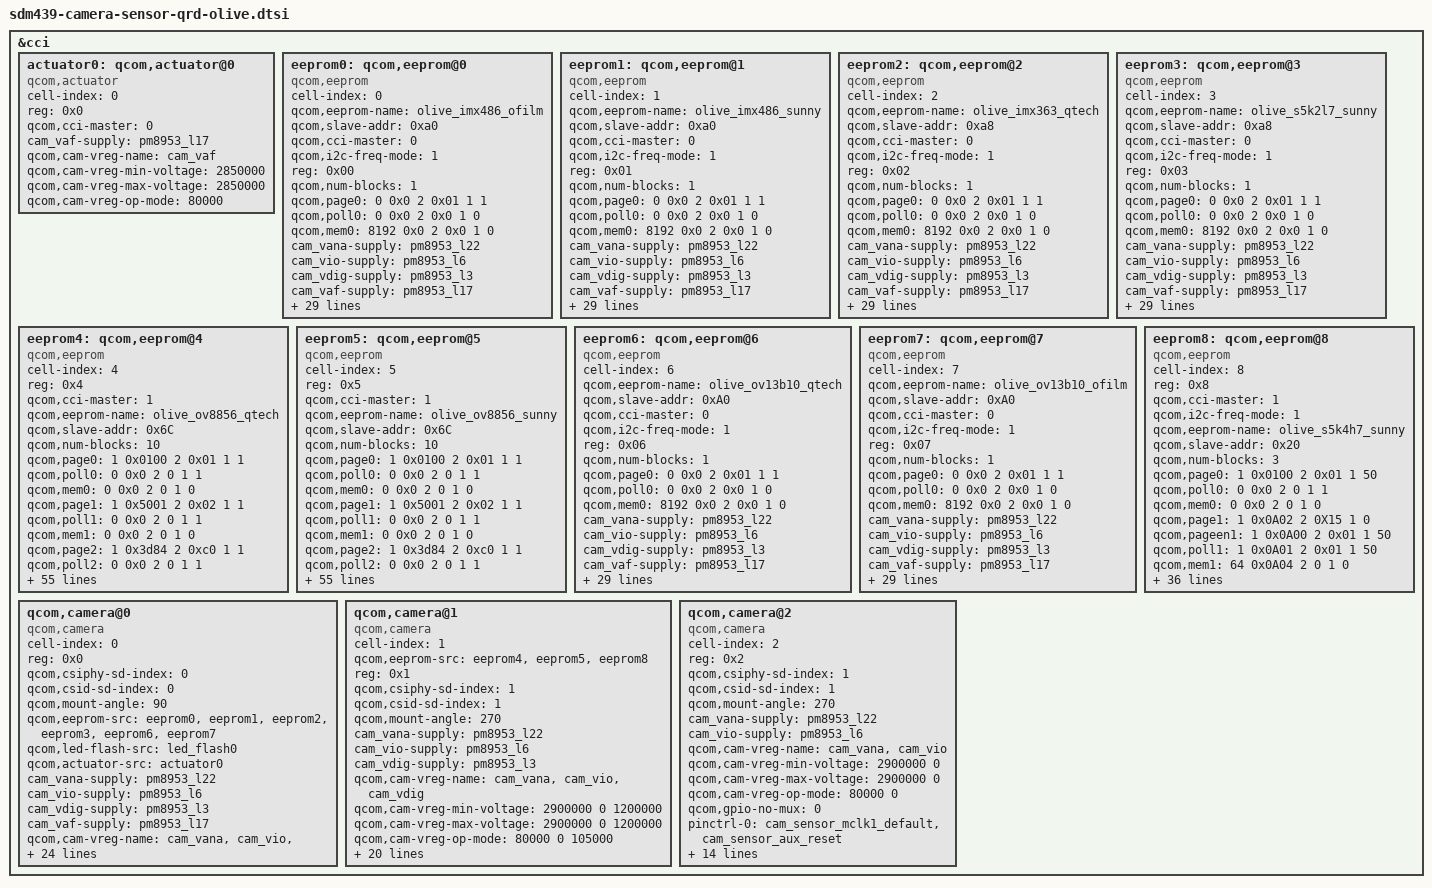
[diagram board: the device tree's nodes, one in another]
/*
 * Copyright (c) 2015-2016, 2018 The Linux Foundation. All rights reserved.
 * Copyright (C) 2021 XiaoMi, Inc.
 *
 * This program is free software; you can redistribute it and/or modify
 * it under the terms of the GNU General Public License version 2 and
 * only version 2 as published by the Free Software Foundation.
 *
 * This program is distributed in the hope that it will be useful,
 * but WITHOUT ANY WARRANTY; without even the implied warranty of
 * MERCHANTABILITY or FITNESS FOR A PARTICULAR PURPOSE.  See the
 * GNU General Public License for more details.
 */

#include <dt-bindings/clock/msm-clocks-8952.h>


&cci {
	actuator0: qcom,actuator@0 {
		cell-index = <0>;
		reg = <0x0>;
		compatible = "qcom,actuator";
		qcom,cci-master = <0>;
		cam_vaf-supply = <&pm8953_l17>;
		qcom,cam-vreg-name = "cam_vaf";
		qcom,cam-vreg-min-voltage = <2850000>;
		qcom,cam-vreg-max-voltage = <2850000>;
		qcom,cam-vreg-op-mode = <80000>;
	};

	eeprom0: qcom,eeprom@0 {
		cell-index = <0>;
		qcom,eeprom-name = "olive_imx486_ofilm";
		compatible = "qcom,eeprom";
		qcom,slave-addr = <0xa0>;
		qcom,cci-master = <0>;
		qcom,i2c-freq-mode = <1>;
		reg = <0x00>;
		qcom,num-blocks = <1>;
		qcom,page0 = <0 0x0 2 0x01 1 1>;
		qcom,poll0 = <0 0x0 2 0x0 1 0>;
		qcom,mem0 = <8192 0x0 2 0x0 1 0>;
		cam_vana-supply = <&pm8953_l22>;
		cam_vio-supply = <&pm8953_l6>;
		cam_vdig-supply = <&pm8953_l3>;
		cam_vaf-supply = <&pm8953_l17>;
		qcom,cam-vreg-name = "cam_vana", "cam_vio","cam_vdig", "cam_vaf";
		qcom,cam-vreg-min-voltage = <2900000 0 1200000 2850000>;
		qcom,cam-vreg-max-voltage = <2900000 0 1200000 2850000>;
		qcom,cam-vreg-op-mode = <80000 0 200000 100000>;
		pinctrl-names = "cam_default", "cam_suspend";
		pinctrl-0 = <&cam_sensor_mclk0_default
				&cam_sensor_rear_reset
				&cam_sensor_rear_vana>;
		pinctrl-1 = <&cam_sensor_mclk0_sleep
				&cam_sensor_rear_reset_sleep
				&cam_sensor_rear_vana_sleep>;
		gpios = <&tlmm 26 0>,
			<&tlmm 36 0>,
			<&tlmm 35 0>;
		qcom,gpio-reset = <1>;
		qcom,gpio-vana = <2>;
		qcom,gpio-req-tbl-num = <0 1 2>;
		qcom,gpio-req-tbl-flags = <1 0 0>;
		qcom,gpio-req-tbl-label = "CAMIF_MCLK0",
			"CAM_RESET0",
			"CAM_VANA";
		status = "ok";
		clocks = <&clock_gcc clk_mclk0_clk_src>,
			<&clock_gcc clk_gcc_camss_mclk0_clk>;
		clock-names = "cam_src_clk", "cam_clk";
		qcom,clock-rates = <24000000 0>;
		qcom,cam-power-seq-type = "sensor_vreg", "sensor_vreg",
				"sensor_vreg", "sensor_clk",
				"sensor_gpio";
		qcom,cam-power-seq-val = "cam_vdig", "cam_vana", "cam_vio",
			"sensor_cam_mclk","sensor_gpio_reset";
		qcom,cam-power-seq-cfg-val = <0 0 0 24000000 1>;
		qcom,cam-power-seq-delay = <0 0 0 1 5>;
	};

	eeprom1: qcom,eeprom@1 {
		cell-index = <1>;
		qcom,eeprom-name = "olive_imx486_sunny";
		compatible = "qcom,eeprom";
		qcom,slave-addr = <0xa0>;
		qcom,cci-master = <0>;
		qcom,i2c-freq-mode = <1>;
		reg = <0x01>;
		qcom,num-blocks = <1>;
		qcom,page0 = <0 0x0 2 0x01 1 1>;
		qcom,poll0 = <0 0x0 2 0x0 1 0>;
		qcom,mem0 = <8192 0x0 2 0x0 1 0>;
		cam_vana-supply = <&pm8953_l22>;
		cam_vio-supply = <&pm8953_l6>;
		cam_vdig-supply = <&pm8953_l3>;
		cam_vaf-supply = <&pm8953_l17>;
		qcom,cam-vreg-name = "cam_vana", "cam_vio",
			"cam_vdig", "cam_vaf";
		qcom,cam-vreg-min-voltage = <2900000 0 1200000 2850000>;
		qcom,cam-vreg-max-voltage = <2900000 0 1200000 2850000>;
		qcom,cam-vreg-op-mode = <80000 0 200000 100000>;
		pinctrl-names = "cam_default", "cam_suspend";
		pinctrl-0 = <&cam_sensor_mclk0_default
				&cam_sensor_rear_reset
				&cam_sensor_rear_vana>;
		pinctrl-1 = <&cam_sensor_mclk0_sleep
				&cam_sensor_rear_reset_sleep
				&cam_sensor_rear_vana_sleep>;
		gpios = <&tlmm 26 0>,
			<&tlmm 36 0>,
			<&tlmm 35 0>;
		qcom,gpio-reset = <1>;
		qcom,gpio-vana = <2>;
		qcom,gpio-req-tbl-num = <0 1 2>;
		qcom,gpio-req-tbl-flags = <1 0 0>;
		qcom,gpio-req-tbl-label = "CAMIF_MCLK0",
			"CAM_RESET0",
			"CAM_VANA";
		status = "ok";
		clocks = <&clock_gcc clk_mclk0_clk_src>,
			<&clock_gcc clk_gcc_camss_mclk0_clk>;
		clock-names = "cam_src_clk", "cam_clk";
		qcom,clock-rates = <24000000 0>;
		qcom,cam-power-seq-type = "sensor_vreg", "sensor_vreg",
				"sensor_vreg", "sensor_clk",
				"sensor_gpio";
		qcom,cam-power-seq-val = "cam_vdig", "cam_vana", "cam_vio",
			"sensor_cam_mclk","sensor_gpio_reset";
		qcom,cam-power-seq-cfg-val = <0 0 0 24000000 1>;
		qcom,cam-power-seq-delay = <0 0 0 1 5>;
	};

	eeprom2: qcom,eeprom@2 {
		cell-index = <2>;
		qcom,eeprom-name = "olive_imx363_qtech";
		compatible = "qcom,eeprom";
		qcom,slave-addr = <0xa8>;
		qcom,cci-master = <0>;
		qcom,i2c-freq-mode = <1>;
		reg = <0x02>;
		qcom,num-blocks = <1>;
		qcom,page0 = <0 0x0 2 0x01 1 1>;
		qcom,poll0 = <0 0x0 2 0x0 1 0>;
		qcom,mem0 = <8192 0x0 2 0x0 1 0>;
		cam_vana-supply = <&pm8953_l22>;
		cam_vio-supply = <&pm8953_l6>;
		cam_vdig-supply = <&pm8953_l3>;
		cam_vaf-supply = <&pm8953_l17>;
		qcom,cam-vreg-name = "cam_vana", "cam_vio",
			"cam_vdig", "cam_vaf";
		qcom,cam-vreg-min-voltage = <2900000 0 1200000 2850000>;
		qcom,cam-vreg-max-voltage = <2900000 0 1200000 2850000>;
		qcom,cam-vreg-op-mode = <80000 0 200000 100000>;
		pinctrl-names = "cam_default", "cam_suspend";
		pinctrl-0 = <&cam_sensor_mclk0_default
				&cam_sensor_rear_reset
				&cam_sensor_rear_vana>;
		pinctrl-1 = <&cam_sensor_mclk0_sleep
				&cam_sensor_rear_reset_sleep
				&cam_sensor_rear_vana_sleep>;
		gpios = <&tlmm 26 0>,
			<&tlmm 36 0>,
			<&tlmm 35 0>;
		qcom,gpio-reset = <1>;
		qcom,gpio-vana = <2>;
		qcom,gpio-req-tbl-num = <0 1 2>;
		qcom,gpio-req-tbl-flags = <1 0 0>;
		qcom,gpio-req-tbl-label = "CAMIF_MCLK0",
			"CAM_RESET0",
			"CAM_VANA";
		status = "ok";
		clocks = <&clock_gcc clk_mclk0_clk_src>,
			<&clock_gcc clk_gcc_camss_mclk0_clk>;
		clock-names = "cam_src_clk", "cam_clk";
		qcom,clock-rates = <24000000 0>;
		qcom,cam-power-seq-type = "sensor_vreg", "sensor_vreg",
				"sensor_vreg", "sensor_clk",
				"sensor_gpio";
		qcom,cam-power-seq-val = "cam_vdig", "cam_vana", "cam_vio",
			"sensor_cam_mclk","sensor_gpio_reset";
		qcom,cam-power-seq-cfg-val = <0 0 0 24000000 1>;
		qcom,cam-power-seq-delay = <0 0 0 1 5>;
	};

	eeprom3: qcom,eeprom@3 {
		cell-index = <3>;
		qcom,eeprom-name = "olive_s5k2l7_sunny";
		compatible = "qcom,eeprom";
		qcom,slave-addr = <0xa8>;
		qcom,cci-master = <0>;
		qcom,i2c-freq-mode = <1>;
		reg = <0x03>;
		qcom,num-blocks = <1>;
		qcom,page0 = <0 0x0 2 0x01 1 1>;
		qcom,poll0 = <0 0x0 2 0x0 1 0>;
		qcom,mem0 = <8192 0x0 2 0x0 1 0>;
		cam_vana-supply = <&pm8953_l22>;
		cam_vio-supply = <&pm8953_l6>;
		cam_vdig-supply = <&pm8953_l3>;
		cam_vaf-supply = <&pm8953_l17>;
		qcom,cam-vreg-name = "cam_vana", "cam_vio",
			"cam_vdig", "cam_vaf";
		qcom,cam-vreg-min-voltage = <2900000 0 1200000 2850000>;
		qcom,cam-vreg-max-voltage = <2900000 0 1200000 2850000>;
		qcom,cam-vreg-op-mode = <80000 0 200000 100000>;
		pinctrl-names = "cam_default", "cam_suspend";
		pinctrl-0 = <&cam_sensor_mclk0_default
				&cam_sensor_rear_reset
				&cam_sensor_rear_vana>;
		pinctrl-1 = <&cam_sensor_mclk0_sleep
				&cam_sensor_rear_reset_sleep
				&cam_sensor_rear_vana_sleep>;
		gpios = <&tlmm 26 0>,
			<&tlmm 36 0>,
			<&tlmm 35 0>;
		qcom,gpio-reset = <1>;
		qcom,gpio-vana = <2>;
		qcom,gpio-req-tbl-num = <0 1 2>;
		qcom,gpio-req-tbl-flags = <1 0 0>;
		qcom,gpio-req-tbl-label = "CAMIF_MCLK0",
			"CAM_RESET0",
			"CAM_VANA";
		status = "ok";
		clocks = <&clock_gcc clk_mclk0_clk_src>,
			<&clock_gcc clk_gcc_camss_mclk0_clk>;
		clock-names = "cam_src_clk", "cam_clk";
		qcom,clock-rates = <24000000 0>;
		qcom,cam-power-seq-type = "sensor_vreg", "sensor_vreg",
				"sensor_vreg", "sensor_clk",
				"sensor_gpio";
		qcom,cam-power-seq-val = "cam_vdig", "cam_vana", "cam_vio",
			"sensor_cam_mclk","sensor_gpio_reset";
		qcom,cam-power-seq-cfg-val = <0 0 0 24000000 1>;
		qcom,cam-power-seq-delay = <0 0 0 1 5>;
	};

	eeprom4: qcom,eeprom@4 {
		cell-index = <4>;
		reg = <0x4>;
		compatible = "qcom,eeprom";
		qcom,cci-master = <1>;

		qcom,eeprom-name = "olive_ov8856_qtech";
		qcom,slave-addr = <0x6C>;

		qcom,num-blocks = <10>;
		qcom,page0 = <1 0x0100 2 0x01 1 1>;
		qcom,poll0 = <0 0x0 2 0 1 1>;
		qcom,mem0 = <0 0x0 2 0 1 0>;

		qcom,page1 = <1 0x5001 2 0x02 1 1>;
		qcom,poll1 = <0 0x0 2 0 1 1>;
		qcom,mem1 = <0 0x0 2 0 1 0>;

		qcom,page2 = <1 0x3d84 2 0xc0 1 1>;
		qcom,poll2 = <0 0x0 2 0 1 1>;
		qcom,mem2 = <0 0x0 2 0 1 0>;

		qcom,page3 = <1 0x3d88 2 0x70 1 1>;
		qcom,poll3 = <0 0x0 2 0 1 1>;
		qcom,mem3 = <0 0x0 2 0 1 0>;

		qcom,page4 = <1 0x3d89 2 0x00 1 1>;
		qcom,poll4 = <0 0x0 2 0 1 1>;
		qcom,mem4 = <0 0x0 2 0 1 0>;

		qcom,page5 = <1 0x3d8a 2 0x72 1 1>;
		qcom,poll5 = <0 0x0 2 0 1 1>;
		qcom,mem5 = <0 0x0 2 0 1 0>;

		qcom,page6 = <1 0x3d8b 2 0x0D 1 1>;
		qcom,poll6 = <0 0x0 2 0 1 1>;
		qcom,mem6 = <0 0x0 2 0 1 0>;

		qcom,page7 = <1 0x3d81 2 0x01 1 0>;
		qcom,poll7 = <0 0x0 2 0 1 1>;
		qcom,mem7 = <0x20E 0x7000 2 0 1 0>;

		qcom,page8 = <0 0 2 0x0 1 10>;
		qcom,poll8 = <0 0x0 2 0 1 1>;
		qcom,mem8 = <1 0x5000 2 0 1 0>;

		qcom,page9 = <1 0x5001 2 0x0a 1 5>;
		qcom,pageen9 = <1 0x0100 2 0x00 1 5>;
		qcom,poll9 = <0 0x0 2 0 1 1>;
		qcom,mem9 = <0 0x0 2 0 1 0>;

		cam_vana-supply = <&pm8953_l22>;
		cam_vio-supply = <&pm8953_l6>;
		cam_vdig-supply = <&pm8953_l3>;
		qcom,cam-vreg-name = "cam_vana", "cam_vio", "cam_vdig";
		qcom,cam-vreg-min-voltage = <2900000 0 1200000>;
		qcom,cam-vreg-max-voltage = <2900000 0 1200000>;
		qcom,cam-vreg-op-mode = <80000 0 105000>;
		qcom,gpio-no-mux = <0>;
		pinctrl-names = "cam_default", "cam_suspend";
		pinctrl-0 = <&cam_sensor_mclk2_default
				&cam_sensor_front_default
				&cam_sensor_rear_vana>;
		pinctrl-1 = <&cam_sensor_mclk2_sleep
				&cam_sensor_front_sleep
				&cam_sensor_rear_vana_sleep>;
		gpios = <&tlmm 28 0>,
			<&tlmm 38 0>,
			<&tlmm 35 0>;
		qcom,gpio-reset = <1>;
		qcom,gpio-vana = <2>;
		qcom,gpio-req-tbl-num = <0 1 2>;
		qcom,gpio-req-tbl-flags = <1 0 0>;
		qcom,gpio-req-tbl-label = "CAMIF_MCLK2",
						"CAM_RESET2",
						"CAM_VANA";
		status = "ok";
		clocks = <&clock_gcc clk_mclk2_clk_src>,
			<&clock_gcc clk_gcc_camss_mclk2_clk>;
		clock-names = "cam_src_clk", "cam_clk";
		qcom,clock-rates = <24000000 0>;
		qcom,cam-power-seq-type = "sensor_vreg",
				"sensor_vreg", "sensor_vreg",
				"sensor_clk", "sensor_gpio";
		qcom,cam-power-seq-val = "cam_vdig",
				"cam_vana", "cam_vio",
				"sensor_cam_mclk", "sensor_gpio_reset";
		qcom,cam-power-seq-cfg-val = <0 0 0 24000000 1>;
		qcom,cam-power-seq-delay = <0 0 0 1 5>;
	};

	eeprom5: qcom,eeprom@5 {
		cell-index = <5>;
		reg = <0x5>;
		compatible = "qcom,eeprom";
		qcom,cci-master = <1>;

		qcom,eeprom-name = "olive_ov8856_sunny";
		qcom,slave-addr = <0x6C>;

		qcom,num-blocks = <10>;
		qcom,page0 = <1 0x0100 2 0x01 1 1>;
		qcom,poll0 = <0 0x0 2 0 1 1>;
		qcom,mem0 = <0 0x0 2 0 1 0>;

		qcom,page1 = <1 0x5001 2 0x02 1 1>;
		qcom,poll1 = <0 0x0 2 0 1 1>;
		qcom,mem1 = <0 0x0 2 0 1 0>;

		qcom,page2 = <1 0x3d84 2 0xc0 1 1>;
		qcom,poll2 = <0 0x0 2 0 1 1>;
		qcom,mem2 = <0 0x0 2 0 1 0>;

		qcom,page3 = <1 0x3d88 2 0x70 1 1>;
		qcom,poll3 = <0 0x0 2 0 1 1>;
		qcom,mem3 = <0 0x0 2 0 1 0>;

		qcom,page4 = <1 0x3d89 2 0x00 1 1>;
		qcom,poll4 = <0 0x0 2 0 1 1>;
		qcom,mem4 = <0 0x0 2 0 1 0>;

		qcom,page5 = <1 0x3d8a 2 0x72 1 1>;
		qcom,poll5 = <0 0x0 2 0 1 1>;
		qcom,mem5 = <0 0x0 2 0 1 0>;

		qcom,page6 = <1 0x3d8b 2 0x0D 1 1>;
		qcom,poll6 = <0 0x0 2 0 1 1>;
		qcom,mem6 = <0 0x0 2 0 1 0>;

		qcom,page7 = <1 0x3d81 2 0x01 1 0>;
		qcom,poll7 = <0 0x0 2 0 1 1>;
		qcom,mem7 = <0x20E 0x7000 2 0 1 0>;

		qcom,page8 = <0 0 2 0x0 1 10>;
		qcom,poll8 = <0 0x0 2 0 1 1>;
		qcom,mem8 = <1 0x5000 2 0 1 0>;

		qcom,page9 = <1 0x5001 2 0x0a 1 5>;
		qcom,pageen9 = <1 0x0100 2 0x00 1 5>;
		qcom,poll9 = <0 0x0 2 0 1 1>;
		qcom,mem9 = <0 0x0 2 0 1 0>;

		cam_vana-supply = <&pm8953_l22>;
		cam_vio-supply = <&pm8953_l6>;
		cam_vdig-supply = <&pm8953_l3>;
		qcom,cam-vreg-name = "cam_vana", "cam_vio", "cam_vdig";
		qcom,cam-vreg-min-voltage = <2900000 0 1200000>;
		qcom,cam-vreg-max-voltage = <2900000 0 1200000>;
		qcom,cam-vreg-op-mode = <80000 0 105000>;
		qcom,gpio-no-mux = <0>;
		pinctrl-names = "cam_default", "cam_suspend";
		pinctrl-0 = <&cam_sensor_mclk2_default
				&cam_sensor_front_default
				&cam_sensor_rear_vana>;
		pinctrl-1 = <&cam_sensor_mclk2_sleep
				&cam_sensor_front_sleep
				&cam_sensor_rear_vana_sleep>;
		gpios = <&tlmm 28 0>,
			<&tlmm 38 0>,
			<&tlmm 35 0>;
		qcom,gpio-reset = <1>;
		qcom,gpio-vana = <2>;
		qcom,gpio-req-tbl-num = <0 1 2>;
		qcom,gpio-req-tbl-flags = <1 0 0>;
		qcom,gpio-req-tbl-label = "CAMIF_MCLK2",
						"CAM_RESET2",
						"CAM_VANA";
		status = "ok";
		clocks = <&clock_gcc clk_mclk2_clk_src>,
			<&clock_gcc clk_gcc_camss_mclk2_clk>;
		clock-names = "cam_src_clk", "cam_clk";
		qcom,clock-rates = <24000000 0>;
		qcom,cam-power-seq-type = "sensor_vreg",
				"sensor_vreg", "sensor_vreg",
				"sensor_clk", "sensor_gpio";
		qcom,cam-power-seq-val = "cam_vdig",
				"cam_vana", "cam_vio",
				"sensor_cam_mclk", "sensor_gpio_reset";
		qcom,cam-power-seq-cfg-val = <0 0 0 24000000 1>;
		qcom,cam-power-seq-delay = <0 0 0 1 5>;
	};

	eeprom6: qcom,eeprom@6 {
		cell-index = <6>;
		qcom,eeprom-name = "olive_ov13b10_qtech";
		compatible = "qcom,eeprom";
		qcom,slave-addr = <0xA0>;
		qcom,cci-master = <0>;
		qcom,i2c-freq-mode = <1>;
		reg = <0x06>;
		qcom,num-blocks = <1>;
		qcom,page0 = <0 0x0 2 0x01 1 1>;
		qcom,poll0 = <0 0x0 2 0x0 1 0>;
		qcom,mem0 = <8192 0x0 2 0x0 1 0>;
		cam_vana-supply = <&pm8953_l22>;
		cam_vio-supply = <&pm8953_l6>;
		cam_vdig-supply = <&pm8953_l3>;
		cam_vaf-supply = <&pm8953_l17>;
		qcom,cam-vreg-name = "cam_vana", "cam_vio",
			"cam_vdig", "cam_vaf";
		qcom,cam-vreg-min-voltage = <2900000 0 1200000 2850000>;
		qcom,cam-vreg-max-voltage = <2900000 0 1200000 2850000>;
		qcom,cam-vreg-op-mode = <80000 0 200000 100000>;
		pinctrl-names = "cam_default", "cam_suspend";
		pinctrl-0 = <&cam_sensor_mclk0_default
			&cam_sensor_rear_reset
			&cam_sensor_rear_vana>;
		pinctrl-1 = <&cam_sensor_mclk0_sleep
			&cam_sensor_rear_reset_sleep
			&cam_sensor_rear_vana_sleep>;
		gpios = <&tlmm 26 0>,
			<&tlmm 36 0>,
			<&tlmm 35 0>;
		qcom,gpio-reset = <1>;
		qcom,gpio-vana = <2>;
		qcom,gpio-req-tbl-num = <0 1 2>;
		qcom,gpio-req-tbl-flags = <1 0 0>;
		qcom,gpio-req-tbl-label = "CAMIF_MCLK0",
			"CAM_RESET0",
			"CAM_VANA";
		status = "ok";
		clocks = <&clock_gcc clk_mclk0_clk_src>,
			<&clock_gcc clk_gcc_camss_mclk0_clk>;
		clock-names = "cam_src_clk", "cam_clk";
		qcom,clock-rates = <24000000 0>;
		qcom,cam-power-seq-type = "sensor_vreg", "sensor_vreg",
			"sensor_vreg", "sensor_clk",
			"sensor_gpio";
		qcom,cam-power-seq-val = "cam_vdig", "cam_vana", "cam_vio",
			"sensor_cam_mclk","sensor_gpio_reset";
		qcom,cam-power-seq-cfg-val = <0 0 0 24000000 1>;
		qcom,cam-power-seq-delay = <0 0 0 1 5>;
	};

    eeprom7: qcom,eeprom@7 {
		cell-index = <7>;
		qcom,eeprom-name = "olive_ov13b10_ofilm";
		compatible = "qcom,eeprom";
		qcom,slave-addr = <0xA0>;
		qcom,cci-master = <0>;
		qcom,i2c-freq-mode = <1>;
		reg = <0x07>;
		qcom,num-blocks = <1>;
		qcom,page0 = <0 0x0 2 0x01 1 1>;
		qcom,poll0 = <0 0x0 2 0x0 1 0>;
		qcom,mem0 = <8192 0x0 2 0x0 1 0>;
		cam_vana-supply = <&pm8953_l22>;
		cam_vio-supply = <&pm8953_l6>;
		cam_vdig-supply = <&pm8953_l3>;
		cam_vaf-supply = <&pm8953_l17>;
		qcom,cam-vreg-name = "cam_vana", "cam_vio",
			"cam_vdig", "cam_vaf";
		qcom,cam-vreg-min-voltage = <2900000 0 1200000 2850000>;
		qcom,cam-vreg-max-voltage = <2900000 0 1200000 2850000>;
		qcom,cam-vreg-op-mode = <80000 0 200000 100000>;
		pinctrl-names = "cam_default", "cam_suspend";
		pinctrl-0 = <&cam_sensor_mclk0_default
			&cam_sensor_rear_reset
			&cam_sensor_rear_vana>;
		pinctrl-1 = <&cam_sensor_mclk0_sleep
			&cam_sensor_rear_reset_sleep
			&cam_sensor_rear_vana_sleep>;
		gpios = <&tlmm 26 0>,
			<&tlmm 36 0>,
			<&tlmm 35 0>;
		qcom,gpio-reset = <1>;
		qcom,gpio-vana = <2>;
		qcom,gpio-req-tbl-num = <0 1 2>;
		qcom,gpio-req-tbl-flags = <1 0 0>;
		qcom,gpio-req-tbl-label = "CAMIF_MCLK0",
			"CAM_RESET0",
			"CAM_VANA";
		status = "ok";
		clocks = <&clock_gcc clk_mclk0_clk_src>,
			<&clock_gcc clk_gcc_camss_mclk0_clk>;
		clock-names = "cam_src_clk", "cam_clk";
		qcom,clock-rates = <24000000 0>;
		qcom,cam-power-seq-type = "sensor_vreg", "sensor_vreg",
			"sensor_vreg", "sensor_clk",
			"sensor_gpio";
		qcom,cam-power-seq-val = "cam_vdig", "cam_vana", "cam_vio",
			"sensor_cam_mclk","sensor_gpio_reset";
		qcom,cam-power-seq-cfg-val = <0 0 0 24000000 1>;
		qcom,cam-power-seq-delay = <0 0 0 1 5>;
	};

	eeprom8: qcom,eeprom@8 {
		cell-index = <8>;
		reg = <0x8>;
		compatible = "qcom,eeprom";
		qcom,cci-master = <1>;
		qcom,i2c-freq-mode = <1>;

		qcom,eeprom-name = "olive_s5k4h7_sunny";
		qcom,slave-addr = <0x20>;

		qcom,num-blocks = <3>;

		qcom,page0 = <1 0x0100 2 0x01 1 50>;
		qcom,poll0 = <0 0x0 2 0 1 1>;
		qcom,mem0 = <0 0x0 2 0 1 0>;

		qcom,page1   = <1    0x0A02 2 0X15 1 0>;  //switch page 21
		qcom,pageen1 = <1    0x0A00 2 0x01 1 50>; //page enable
		qcom,poll1   = <1    0x0A01 2 0x01 1 50>;   //check cmd result
		qcom,mem1    = <64   0x0A04 2 0 1 0>;     //read data

		qcom,page2   = <1    0x0A02 2 0X16 1 0>;  //switch page 22
		qcom,pageen2 = <1    0x0A00 2 0x01 1 50>; //page enable
		qcom,poll2   = <1    0x0A01 2 0x01 1 50>;   //check cmd result
		qcom,mem2    = <64   0x0A04 2 0 1 0>;     //read data
/*
		qcom,page3   = <1    0x0A02 2 0X00 1 0>;  //switch page 23
		qcom,pageen3 = <1    0x0A00 2 0X01 1 5>; //page enable
		qcom,poll3   = <1    0x0A01 2 0X01 1 5>;   //check cmd result
		qcom,mem3    = <2   0x0A3D 2 0 1 50>;     //read data

*/
		cam_vana-supply = <&pm8953_l22>;
		cam_vio-supply = <&pm8953_l6>;
		cam_vdig-supply = <&pm8953_l3>;
		qcom,cam-vreg-name = "cam_vana", "cam_vio", "cam_vdig";
		qcom,cam-vreg-min-voltage = <2900000 0 1200000>;
		qcom,cam-vreg-max-voltage = <2900000 0 1200000>;
		qcom,cam-vreg-op-mode = <80000 0 105000>;
		qcom,gpio-no-mux = <0>;
		pinctrl-names = "cam_default", "cam_suspend";
		pinctrl-0 = <&cam_sensor_mclk2_default
				&cam_sensor_front_default
				&cam_sensor_rear_vana>;
		pinctrl-1 = <&cam_sensor_mclk2_sleep
				&cam_sensor_front_sleep
				&cam_sensor_rear_vana_sleep>;
		gpios = <&tlmm 28 0>,
			<&tlmm 38 0>,
			<&tlmm 35 0>;
		qcom,gpio-reset = <1>;
		qcom,gpio-vana = <2>;
		qcom,gpio-req-tbl-num = <0 1 2>;
		qcom,gpio-req-tbl-flags = <1 0 0>;
		qcom,gpio-req-tbl-label = "CAMIF_MCLK2",
						"CAM_RESET2",
						"CAM_VANA";
		status = "ok";
		clocks = <&clock_gcc clk_mclk2_clk_src>,
			<&clock_gcc clk_gcc_camss_mclk2_clk>;
		clock-names = "cam_src_clk", "cam_clk";
		qcom,clock-rates = <24000000 0>;
		qcom,cam-power-seq-type = "sensor_vreg",
				"sensor_vreg", "sensor_vreg",
				"sensor_gpio","sensor_clk";
		qcom,cam-power-seq-val = "cam_vdig",
				"cam_vana", "cam_vio",
				"sensor_gpio_reset","sensor_cam_mclk";
		qcom,cam-power-seq-cfg-val = <0 0 0 1 24000000>;
		qcom,cam-power-seq-delay = <0 0 2 5 5>;
	};

	qcom,camera@0 {
		cell-index = <0>;
		compatible = "qcom,camera";
		reg = <0x0>;
		qcom,csiphy-sd-index = <0>;
		qcom,csid-sd-index = <0>;
		qcom,mount-angle = <90>;
		qcom,eeprom-src = <&eeprom0 &eeprom1 &eeprom2 &eeprom3 &eeprom6 &eeprom7>;
		qcom,led-flash-src = <&led_flash0>;
		qcom,actuator-src = <&actuator0>;
		cam_vana-supply = <&pm8953_l22>;
		cam_vio-supply = <&pm8953_l6>;
		cam_vdig-supply = <&pm8953_l3>;
		cam_vaf-supply = <&pm8953_l17>;
		qcom,cam-vreg-name = "cam_vana", "cam_vio", "cam_vdig", "cam_vaf";
		qcom,cam-vreg-min-voltage = <2900000 0 1050000 2850000>;
		qcom,cam-vreg-max-voltage = <2900000 0 1200000 2850000>;
		qcom,cam-vreg-op-mode = <80000 0 200000 100000>;
		pinctrl-names = "cam_default", "cam_suspend";
		pinctrl-0 = <&cam_sensor_mclk0_default
				&cam_sensor_rear_reset
				&cam_sensor_rear_vana>;
		pinctrl-1 = <&cam_sensor_mclk0_sleep
				&cam_sensor_rear_reset_sleep
				&cam_sensor_rear_vana_sleep>;
		gpios = <&tlmm 26 0>,
			<&tlmm 36 0>,
			<&tlmm 35 0>;
		qcom,gpio-reset = <1>;
		qcom,gpio-vana = <2>;
		qcom,gpio-req-tbl-num = <0 1 2>;
		qcom,gpio-req-tbl-flags = <1 0 0>;
		qcom,gpio-req-tbl-label = "CAMIF_MCLK0",
			"CAM_RESET0", "CAM_VANA";
		qcom,sensor-position = <0>;
		qcom,sensor-mode = <0>;
		qcom,cci-master = <0>;
		status = "ok";
		clocks = <&clock_gcc clk_mclk0_clk_src>,
			<&clock_gcc clk_gcc_camss_mclk0_clk>;
		clock-names = "cam_src_clk", "cam_clk";
		qcom,clock-rates = <24000000 0>;
	};

	qcom,camera@1 {
		cell-index = <1>;
		compatible = "qcom,camera";
		qcom,eeprom-src = <&eeprom4 &eeprom5 &eeprom8>;
		reg = <0x1>;
		qcom,csiphy-sd-index = <1>;
		qcom,csid-sd-index = <1>;
		qcom,mount-angle = <270>;
		cam_vana-supply = <&pm8953_l22>;
		cam_vio-supply = <&pm8953_l6>;
		cam_vdig-supply = <&pm8953_l3>;
		qcom,cam-vreg-name = "cam_vana", "cam_vio", "cam_vdig";
		qcom,cam-vreg-min-voltage = <2900000 0 1200000>;
		qcom,cam-vreg-max-voltage = <2900000 0 1200000>;
		qcom,cam-vreg-op-mode = <80000 0 105000>;
		qcom,gpio-no-mux = <0>;
		pinctrl-names = "cam_default", "cam_suspend";
		pinctrl-0 = <&cam_sensor_mclk2_default
				&cam_sensor_front_default
				&cam_sensor_rear_vana>;
		pinctrl-1 = <&cam_sensor_mclk2_sleep
				&cam_sensor_front_sleep
				&cam_sensor_rear_vana_sleep>;
		gpios = <&tlmm 28 0>,
			<&tlmm 38 0>,
			<&tlmm 35 0>;
		qcom,gpio-reset = <1>;
		qcom,gpio-vana = <2>;
		qcom,gpio-req-tbl-num = <0 1 2>;
		qcom,gpio-req-tbl-flags = <1 0 0>;
		qcom,gpio-req-tbl-label = "CAMIF_MCLK2",
								"CAM_RESET2",
								"CAM_VANA";
		qcom,sensor-position = <1>;
		qcom,sensor-mode = <0>;
		qcom,cci-master = <1>;
		status = "ok";
		clocks = <&clock_gcc clk_mclk2_clk_src>,
			<&clock_gcc clk_gcc_camss_mclk2_clk>;
		clock-names = "cam_src_clk", "cam_clk";
		qcom,clock-rates = <24000000 0>;
	};

	qcom,camera@2 {
		cell-index = <2>;
		compatible = "qcom,camera";
		reg = <0x2>;
		qcom,csiphy-sd-index = <1>;
		qcom,csid-sd-index = <1>;
		qcom,mount-angle = <270>;
		cam_vana-supply = <&pm8953_l22>;
		cam_vio-supply = <&pm8953_l6>;
		qcom,cam-vreg-name = "cam_vana", "cam_vio";
		qcom,cam-vreg-min-voltage = <2900000 0>;
		qcom,cam-vreg-max-voltage = <2900000 0>;
		qcom,cam-vreg-op-mode = <80000 0>;
		qcom,gpio-no-mux = <0>;
		pinctrl-names = "cam_default", "cam_suspend";
		pinctrl-0 = <&cam_sensor_mclk1_default
				&cam_sensor_aux_reset>;
		pinctrl-1 = <&cam_sensor_mclk1_sleep
				&cam_sensor_aux_reset_sleep>;
		gpios = <&tlmm 27 0>,
			<&tlmm 40 0>;
		qcom,gpio-reset = <1>;
		qcom,gpio-req-tbl-num = <0 1>;
		qcom,gpio-req-tbl-flags = <1 0>;
		qcom,gpio-req-tbl-label = "CAMIF_MCLK1",
								"CAM_RESET1";
		qcom,sensor-position = <0>;
		qcom,sensor-mode = <0>;
		qcom,cci-master = <1>;
		status = "ok";
		clocks = <&clock_gcc clk_mclk1_clk_src>,
			<&clock_gcc clk_gcc_camss_mclk1_clk>;
		clock-names = "cam_src_clk", "cam_clk";
		qcom,clock-rates = <24000000 0>;
	};
};
